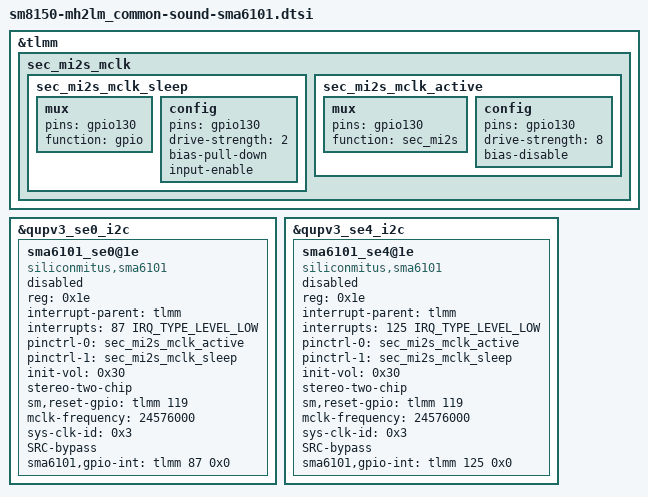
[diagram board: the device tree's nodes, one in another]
/*
 * Copyright (c) 2018, The Linux Foundation. All rights reserved.
 *
 * This program is free software; you can redistribute it and/or modify
 * it under the terms of the GNU General Public License version 2 and
 * only version 2 as published by the Free Software Foundation.
 *
 * This program is distributed in the hope that it will be useful,
 * but WITHOUT ANY WARRANTY; without even the implied warranty of
 * MERCHANTABILITY or FITNESS FOR A PARTICULAR PURPOSE.  See the
 * GNU General Public License for more details.
 */


&tlmm {
	sec_mi2s_mclk {
		sec_mi2s_mclk_sleep: sec_mi2s_mclk_sleep {
			mux {
				pins = "gpio130";
				function = "gpio";
			};

			config {
				pins = "gpio130";
				drive-strength = <2>;   /* 2 mA */
				bias-pull-down;         /* PULL DOWN */
				input-enable;
			};
		};

		sec_mi2s_mclk_active: sec_mi2s_mclk_active {
			mux {
				pins = "gpio130";
				function = "sec_mi2s";
			};

			config {
				pins = "gpio130";
				drive-strength = <8>;   /* 8 mA */
				bias-disable;           /* NO PULL */
			};
		};
	};
};

/* for HDK */
&qupv3_se0_i2c{ /* QUPV3 SE0  */
	status = "ok";
	sma6101_se0@1e {
		compatible = "siliconmitus,sma6101";
		reg = <0x1e>;
		interrupt-parent = <&tlmm>;
		interrupts = <87 IRQ_TYPE_LEVEL_LOW>;

		pinctrl-names = "sec_mi2s_mclk_active", "sec_mi2s_mclk_sleep";
		pinctrl-0 = <&sec_mi2s_mclk_active>;
		pinctrl-1 = <&sec_mi2s_mclk_sleep>;

		init-vol = <0x30>;
		stereo-two-chip;
		sm,reset-gpio = <&tlmm 119 0x0>;

		/* enable external-clock if sys-clk-id is 0x1 */
		/* external-clock; */
		/* use this frequency if sys-clk-id is not 0x3 */
		mclk-frequency = <24576000>;
		/* SMA6101_EXTERNAL_CLOCK_19_2 : 0x0, SMA6101_EXTERNAL_CLOCK_24_576 : 0x1, SMA6101_PLL_CLKIN_MCLK : 0x2, SMA6101_PLL_CLKIN_BCLK : 0x3 */
		sys-clk-id = <0x3>;
		SRC-bypass;

		/* registers-of-amp = <0x0e 0xae>,<0x14 0x18>,<0x19 0x20>,<0x37 0x10>,<0x3c 0x30>,
				   <0x97 0xec>,
				   <0x23 0x95>,<0x24 0x0>,<0x25 0x0>,<0x26 0x78>; */
		sma6101,gpio-int= <&tlmm 87 0x0>;

		status = "disabled";
	};
};
/* for Rev0.1 */
&qupv3_se4_i2c{ /* QUPV3 SE4  */
	sma6101_se4@1e {
		compatible = "siliconmitus,sma6101";
		reg = <0x1e>;
		interrupt-parent = <&tlmm>;
		interrupts = <125 IRQ_TYPE_LEVEL_LOW>;

		pinctrl-names = "sec_mi2s_mclk_active", "sec_mi2s_mclk_sleep";
		pinctrl-0 = <&sec_mi2s_mclk_active>;
		pinctrl-1 = <&sec_mi2s_mclk_sleep>;

		init-vol = <0x30>;
		stereo-two-chip;
		sm,reset-gpio = <&tlmm 119 0x0>;

		/* enable external-clock if sys-clk-id is 0x1 */
		/* external-clock; */
		/* use this frequency if sys-clk-id is not 0x3 */
		mclk-frequency = <24576000>;
		/* SMA6101_EXTERNAL_CLOCK_19_2 : 0x0, SMA6101_EXTERNAL_CLOCK_24_576 : 0x1, SMA6101_PLL_CLKIN_MCLK : 0x2, SMA6101_PLL_CLKIN_BCLK : 0x3 */
		sys-clk-id = <0x3>;
		SRC-bypass;

		/* registers-of-amp = <0x0e 0xae>,<0x14 0x18>,<0x19 0x20>,<0x37 0x10>,<0x3c 0x30>,
				   <0x97 0xec>,
				   <0x23 0x95>,<0x24 0x0>,<0x25 0x0>,<0x26 0x78>; */
		sma6101,gpio-int= <&tlmm 125 0x0>;

		status = "disabled";
	};
};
